# ESP32 register map
Vendor: ESPRESSIF SYSTEMS (SHANGHAI) CO., LTD.; Series: ESP32 Series; File version: 17
CPU: Xtensa LX6 r0p0, little endian, no MPU, FPU, 0 interrupt priority bits
Address unit: 32 bits
Registers are 32-bit, read-write, reset 0x0 unless marked. A register's access mark holds for its fields unless they carry their own. Offsets are from the block's base; [hi:lo] are bit positions; lines under a group give offsets from that group; {n}, {i} and the like mark numbered series.

## LEDC — LED Control PWM (Pulse Width Modulation)
Base 0x3FF59000
{0x0+0x14*i} HSCH{i} (i=0..7) group — Cluster HSCH{i}, containing HSCH?_CONF0, HSCH?_HPOINT, HSCH?_DUTY, HSCH?_CONF1, HSCH?_DUTY_R
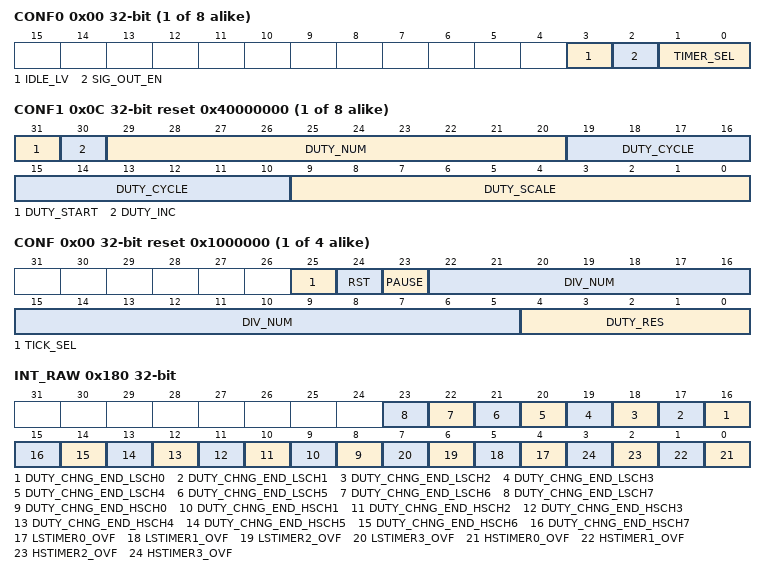
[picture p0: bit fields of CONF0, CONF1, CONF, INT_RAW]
  0x00 CONF0
    [3] IDLE_LV — This bit is used to control the output value when high speed channel0 is off.
    [2] SIG_OUT_EN — This is the output enable control bit for high speed channel0
    [1:0] TIMER_SEL — There are four high speed timers the two bits are used to select one of them for high speed channel0. 2'b00: seletc hstimer0. 2'b01: select hstimer1. 2'b10: select hstimer2. 2'b11: select hstimer3.
  0x04 HPOINT
    [19:0] HPOINT — The output value changes to high when htimerx(x=[0 3]) selected by high speed channel0 has reached reg_hpoint_hsch0[19:0]
  0x08 DUTY
    [24:0] DUTY — This register represents the current duty of the output signal for high speed channel0.
  0x0C CONF1 reset 0x40000000
    [31] DUTY_START — When reg_duty_num_hsch0 reg_duty_cycle_hsch0 and reg_duty_scale_hsch0 has been configured. these register won't take effect until set reg_duty_start_hsch0. this bit is automatically cleared by hardware.
    [30] DUTY_INC — This register is used to increase the duty of output signal or decrease the duty of output signal for high speed channel0.
    [29:20] DUTY_NUM — This register is used to control the num of increased or decreased times for high speed channel0.
    [19:10] DUTY_CYCLE — This register is used to increase or decrease the duty every reg_duty_cycle_hsch0 cycles for high speed channel0.
    [9:0] DUTY_SCALE — This register controls the increase or decrease step scale for high speed channel0.
  0x10 DUTY_R ro
    [24:0] DUTY_R — This register represents the current duty cycle of the output signal for high-speed channel %s
{0xA0+0x14*i} LSCH{i} (i=0..7) group — Cluster LSCH{i}, containing LSCH?_CONF0, LSCH?_HPOINT, LSCH?_DUTY, LSCH?_CONF1, LSCH?_DUTY_R
  0x00 CONF0
    [4] PARA_UP — This bit is used to update register LEDC_LSCH0_HPOINT and LEDC_LSCH0_DUTY for low speed channel0.
    [3] IDLE_LV — This bit is used to control the output value when low speed channel0 is off.
    [2] SIG_OUT_EN — This is the output enable control bit for low speed channel0.
    [1:0] TIMER_SEL — There are four low speed timers the two bits are used to select one of them for low speed channel0. 2'b00: seletc lstimer0. 2'b01: select lstimer1. 2'b10: select lstimer2. 2'b11: select lstimer3.
  0x04 HPOINT
    [19:0] HPOINT — The output value changes to high when lstimerx(x=[0 3]) selected by low speed channel0 has reached reg_hpoint_lsch0[19:0]
  0x08 DUTY
    [24:0] DUTY — This register represents the current duty of the output signal for low speed channel0.
  0x0C CONF1 reset 0x40000000
    [31] DUTY_START — When reg_duty_num_hsch1 reg_duty_cycle_hsch1 and reg_duty_scale_hsch1 has been configured. these register won't take effect until set reg_duty_start_hsch1. this bit is automatically cleared by hardware.
    [30] DUTY_INC — This register is used to increase the duty of output signal or decrease the duty of output signal for low speed channel6.
    [29:20] DUTY_NUM — This register is used to control the num of increased or decreased times for low speed channel6.
    [19:10] DUTY_CYCLE — This register is used to increase or decrease the duty every reg_duty_cycle_lsch0 cycles for low speed channel0.
    [9:0] DUTY_SCALE — This register controls the increase or decrease step scale for low speed channel0.
  0x10 DUTY_R ro
    [24:0] DUTY_R — This register represents the current duty cycle of the output signal for low-speed channel %s
{0x140+8i} HSTIMER{i} (i=0..3) group — Cluster HSTIMER{i}, containing HSTIMER?_CONF, HSTIMER?_VALUE
  0x00 CONF reset 0x1000000
    [25] TICK_SEL — This bit is used to choose apb_clk or ref_tick for high speed timer0. 1'b1:apb_clk 0:ref_tick
    [24] RST — This bit is used to reset high speed timer0 the counter will be 0 after reset.
    [23] PAUSE — This bit is used to pause the counter in high speed timer0
    [22:5] DIV_NUM — This register is used to configure parameter for divider in high speed timer0 the least significant eight bits represent the decimal part.
    [4:0] DUTY_RES — This register controls the range of the counter in high speed timer0. the counter range is [0 2**reg_hstimer0_lim] the max bit width for counter is 20.
  0x04 VALUE ro
    [19:0] CNT — software can read this register to get the current counter value in high speed timer0
{0x160+8i} LSTIMER{i} (i=0..3) group — Cluster LSTIMER{i}, containing LSTIMER?_CONF, LSTIMER?_VALUE
  0x00 CONF reset 0x1000000
    [26] PARA_UP — Set this bit to update reg_div_num_lstime0 and reg_lstimer0_lim.
    [25] TICK_SEL — This bit is used to choose slow_clk or ref_tick for low speed timer0. 1'b1:slow_clk 0:ref_tick
    [24] RST — This bit is used to reset low speed timer0 the counter will be 0 after reset.
    [23] PAUSE — This bit is used to pause the counter in low speed timer0.
    [22:5] DIV_NUM — This register is used to configure parameter for divider in low speed timer0 the least significant eight bits represent the decimal part.
    [4:0] DUTY_RES — This register controls the range of the counter in low speed timer0. the counter range is [0 2**reg_lstimer0_lim] the max bit width for counter is 20.
  0x04 VALUE ro
    [19:0] CNT — software can read this register to get the current counter value in low speed timer0.
0x180 INT_RAW
  [n+16] DUTY_CHNG_END_LSCH{n} (n=0..7) — The interrupt raw bit for low speed channel {n} duty change done.
  [n+8] DUTY_CHNG_END_HSCH{n} (n=0..7) — The interrupt raw bit for high speed channel {n} duty change done.
  [n+4] LSTIMER{n}_OVF (n=0..3) — The interrupt raw bit for low speed channel{n} counter overflow.
  [n] HSTIMER{n}_OVF (n=0..3) — The interrupt raw bit for high speed channel{n} counter overflow.
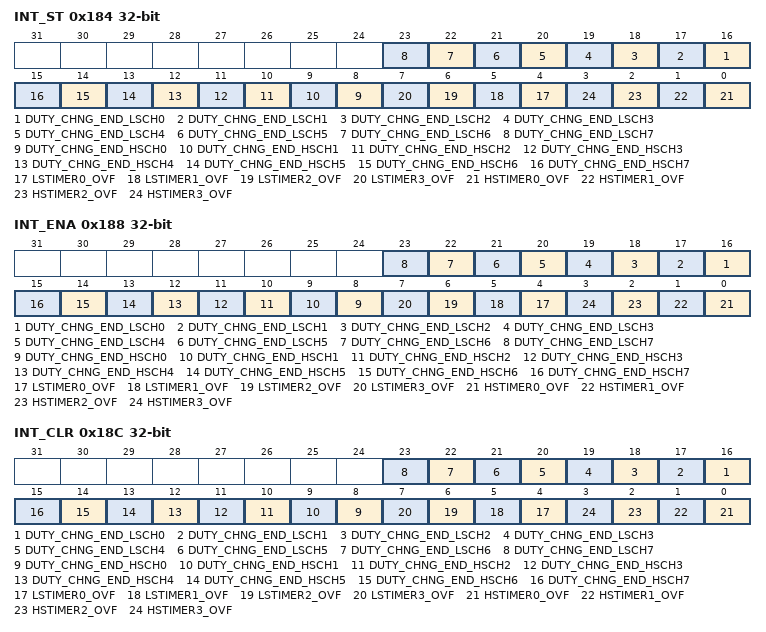
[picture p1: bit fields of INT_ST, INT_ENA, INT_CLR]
0x184 INT_ST ro
  [n+16] DUTY_CHNG_END_LSCH{n} (n=0..7) — The interrupt status bit for low speed channel {n} duty change done event.
  [n+8] DUTY_CHNG_END_HSCH{n} (n=0..7) — The interrupt status bit for high speed channel {n} duty change done event.
  [n+4] LSTIMER{n}_OVF (n=0..3) — The interrupt status bit for low speed channel{n} counter overflow event.
  [n] HSTIMER{n}_OVF (n=0..3) — The interrupt status bit for high speed channel{n} counter overflow event.
0x188 INT_ENA
  [n+16] DUTY_CHNG_END_LSCH{n} (n=0..7) — The interrupt enable bit for low speed channel {n} duty change done interrupt.
  [n+8] DUTY_CHNG_END_HSCH{n} (n=0..7) — The interrupt enable bit for high speed channel {n} duty change done interrupt.
  [n+4] LSTIMER{n}_OVF (n=0..3) — The interrupt enable bit for low speed channel{n} counter overflow interrupt.
  [n] HSTIMER{n}_OVF (n=0..3) — The interrupt enable bit for high speed channel{n} counter overflow interrupt.
0x18C INT_CLR wo
  [n+16] DUTY_CHNG_END_LSCH{n} (n=0..7) write-1-clears — Set this bit to clear low speed channel {n} duty change done interrupt.
  [n+8] DUTY_CHNG_END_HSCH{n} (n=0..7) write-1-clears — Set this bit to clear high speed channel {n} duty change done interrupt.
  [n+4] LSTIMER{n}_OVF (n=0..3) write-1-clears — Set this bit to clear low speed channel{n} counter overflow interrupt.
  [n] HSTIMER{n}_OVF (n=0..3) write-1-clears — Set this bit to clear high speed channel{n} counter overflow interrupt.
0x190 CONF
  [0] APB_CLK_SEL — This bit is used to set the frequency of slow_clk. 1'b1:80mhz 1'b0:8mhz
0x1FC DATE
